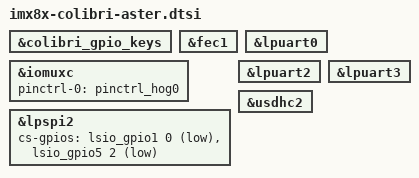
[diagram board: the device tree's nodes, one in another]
&colibri_gpio_keys {
	status = "okay";
};
&fec1 {
	status = "okay";
};
&iomuxc {
	pinctrl-names = "default";
	pinctrl-0 = <&pinctrl_hog0>;
};
&lpspi2 {
	cs-gpios = <&lsio_gpio1 0 GPIO_ACTIVE_LOW>,
		   <&lsio_gpio5 2 GPIO_ACTIVE_LOW>;
};
&lpuart0 {
	status = "okay";
};
&lpuart2 {
	status = "okay";
};
&lpuart3 {
	status = "okay";
};
&usdhc2 {
	status = "okay";
};
